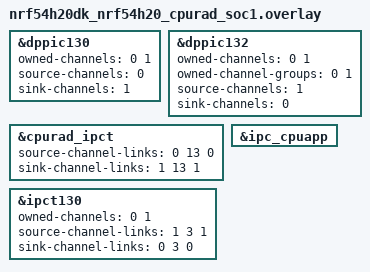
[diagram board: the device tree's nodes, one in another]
/*
 * Copyright (c) 2021 Nordic Semiconductor ASA
 *
 * SPDX-License-Identifier: Apache-2.0
 */

&dppic130 {
    status = "okay";
    owned-channels = <0 1>;
    source-channels = <0>;
    sink-channels = <1>;
};

&dppic132 {
    status = "okay";
    owned-channels = <0 1>;
    owned-channel-groups = <0 1>;
    source-channels = <1>;
    sink-channels = <0>;
};

&cpurad_ipct {
    source-channel-links = <0 13 0>;
    sink-channel-links = <1 13 1>;
};

&ipct130 {
    status = "okay";
    owned-channels = <0 1>;
    source-channel-links = <1 3 1>;
    sink-channel-links = <0 3 0>;
};

ipc0: &ipc_cpuapp { };
